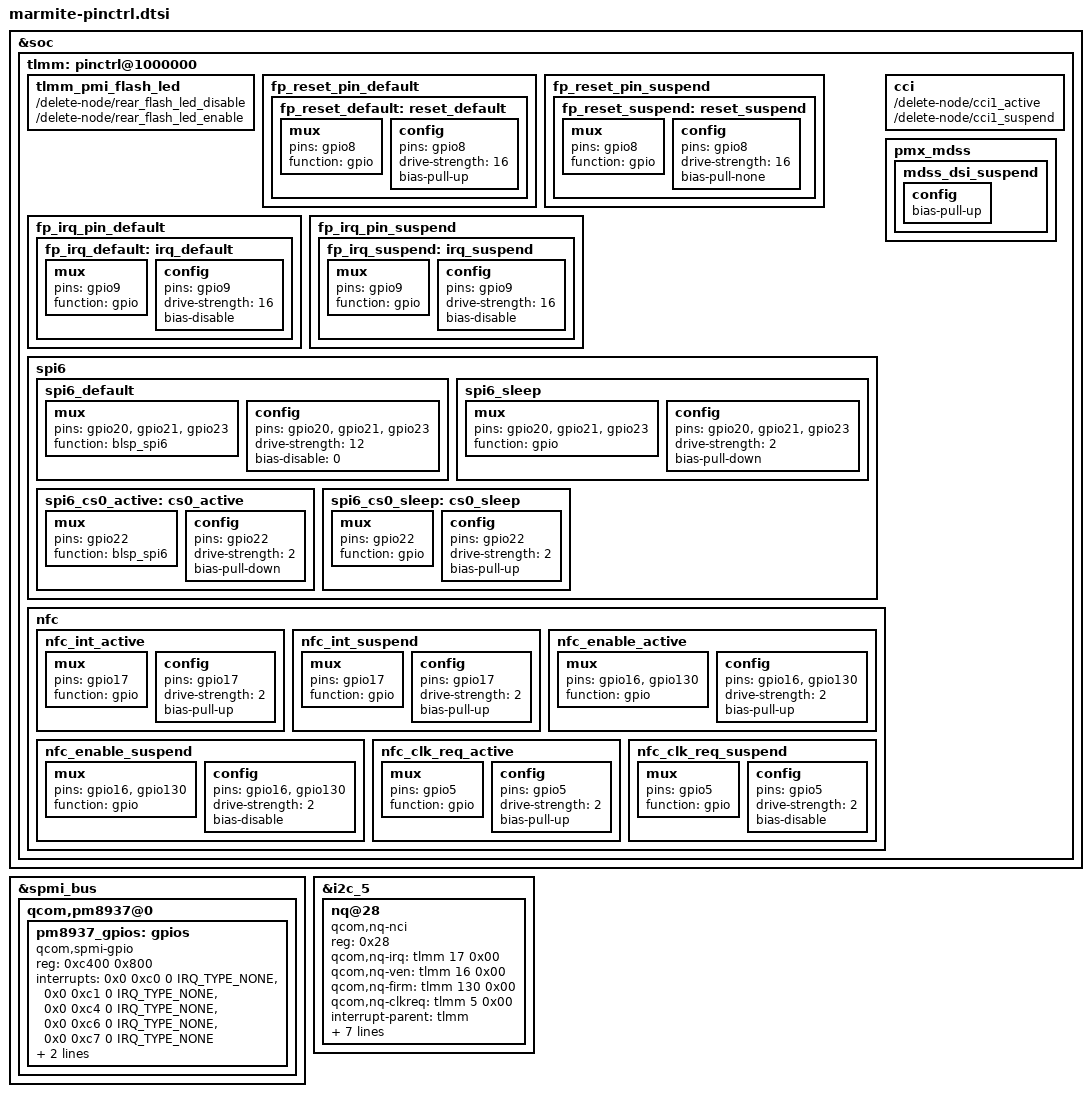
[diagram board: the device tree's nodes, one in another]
/* Copyright (c) 2020, The Linux Foundation. All rights reserved.
*  Copyright (c) 2020, Jebaitedneko.
*
* This program is free software; you can redistribute it and/or modify
* it under the terms of the GNU General Public License version 2 and
* only version 2 as published by the Free Software Foundation.
*
* This program is distributed in the hope that it will be useful,
* but WITHOUT ANY WARRANTY; without even the implied warranty of
* MERCHANTABILITY or FITNESS FOR A PARTICULAR PURPOSE.  See the
* GNU General Public License for more details.
*/

&soc {

	tlmm: pinctrl@1000000 {
		 tlmm_pmi_flash_led {
			  rear_flash_led_disable: /delete-node/rear_flash_led_disable;
			  rear_flash_led_enable: /delete-node/rear_flash_led_enable;
		 };
		 fp_reset_pin_default {
			  fp_reset_default: reset_default {
				   mux {
					    pins = "gpio8";
					    function = "gpio";
				   };

				   config {
					    pins = "gpio8";
					    drive-strength = <16>;
					    bias-pull-up;
				   };
			  };
		 };
		 fp_reset_pin_suspend {
			  fp_reset_suspend: reset_suspend {
				   mux {
					    pins = "gpio8";
					    function = "gpio";
				   };

				   config {
					    pins = "gpio8";
					    drive-strength = <16>;
					    bias-pull-none;
				   };
			  };
		 };

		 fp_irq_pin_default {
			  fp_irq_default: irq_default {
				   mux {
					    pins = "gpio9";
					    function = "gpio";
				   };

				   config {
					    pins = "gpio9";
					    drive-strength = <16>;
					    bias-disable;
				   };
			  };
		 };
		 fp_irq_pin_suspend {
			  fp_irq_suspend: irq_suspend {
				   mux {
					    pins = "gpio9";
					    function = "gpio";
				   };

				   config {
					    pins = "gpio9";
					    drive-strength = <16>;
					    bias-disable;
				   };
			  };
		 };

		 spi6 {
			  spi6_default: spi6_default {
				   mux {
					    pins = "gpio20", "gpio21", "gpio23";
					    function = "blsp_spi6";
				   };

				   config {
					    pins = "gpio20", "gpio21", "gpio23";
					    drive-strength = <12>;
					    bias-disable = <0>;
				   };
			  };

			  spi6_sleep: spi6_sleep {
				   mux {
					    pins = "gpio20", "gpio21", "gpio23";
					    function = "gpio";
				   };

				   config {
					    pins = "gpio20", "gpio21", "gpio23";
					    drive-strength = <2>;
					    bias-pull-down;
				   };
			  };

			  spi6_cs0_active: cs0_active {
				   mux {
					    pins = "gpio22";
					    function = "blsp_spi6";
				   };

				   config {
					    pins = "gpio22";
					    drive-strength = <2>;
					    bias-pull-down;
				   };
			  };

			  spi6_cs0_sleep: cs0_sleep {
				   mux {
					    pins = "gpio22";
					    function = "gpio";
				   };

				   config {
					    pins = "gpio22";
					    drive-strength = <2>;
					    bias-pull-up;
				   };
			  };
		 };

		cci {
			cci1_active: /delete-node/cci1_active;
			cci1_suspend: /delete-node/cci1_suspend;
		};

		pmx_mdss: pmx_mdss {
			mdss_dsi_suspend: mdss_dsi_suspend {
				config {	
					/delete-property/bias-pull-down;
					bias-pull-up;
				};
			};
		};

		nfc {
			nfc_int_active: nfc_int_active {
				/* active state */
				mux {
					/* GPIO 47 NFC Read Interrupt */
					pins = "gpio17";
					function = "gpio";
				};

				config {
					pins = "gpio17";
					drive-strength = <2>; /* 2 MA */
					bias-pull-up;
				};
			};

			nfc_int_suspend: nfc_int_suspend {
				/* sleep state */
				mux {
					/* GPIO 47 NFC Read Interrupt */
					pins = "gpio17";
					function = "gpio";
				};

				config {
					pins = "gpio17";
					drive-strength = <2>; /* 2 MA */
					bias-pull-up;
				};
			};

			nfc_enable_active: nfc_enable_active {
				/* active state */
    				mux {
      					/* 16: NFC ENABLE; 130:NFC FIRM */
      					pins = "gpio16", "gpio130";
      					function = "gpio";
    				};

    				config {
      					pins = "gpio16", "gpio130";
      					drive-strength = <2>; /* 2 MA */
      					bias-pull-up;
    				};
  			};

			nfc_enable_suspend: nfc_enable_suspend {
    				/* sleep state */
    				mux {
      					pins = "gpio16", "gpio130";
      					function = "gpio";
    				};

    				config {
      					pins = "gpio16", "gpio130";
      					drive-strength = <2>; /* 2 MA */
      					bias-disable;
    				};
  			};

  			nfc_clk_req_active: nfc_clk_req_active {
    				/* active state */
    				mux {
      					/* 31: NFC CLOCK REQUEST */
      					pins = "gpio5";
      					function = "gpio";
    				};

    				config {
      					pins = "gpio5";
      					drive-strength = <2>; /* 2 MA */
      					bias-pull-up;
   				};
  			};

 			nfc_clk_req_suspend: nfc_clk_req_suspend {
				/* sleep state */
    				mux {
      					/* 113: NFC CLOCK REQUEST */
      					pins = "gpio5";
      					function = "gpio";
    				};

    				config {
      					pins = "gpio5";
      					drive-strength = <2>; /* 2 MA */
      					bias-disable;
    				};
  			};
		};
	};
};

&spmi_bus {
	qcom,pm8937@0 {
		pm8937_gpios: gpios {
			compatible = "qcom,spmi-gpio";
			/* shifted from <0xc000 0x800>, refer dmesg to get your shifts */
			reg = <0xc400 0x800>;
			interrupts = <0x0 0xc0 0 IRQ_TYPE_NONE>,
				     <0x0 0xc1 0 IRQ_TYPE_NONE>,
				     <0x0 0xc4 0 IRQ_TYPE_NONE>,
				     <0x0 0xc6 0 IRQ_TYPE_NONE>,
				     <0x0 0xc7 0 IRQ_TYPE_NONE>;
			interrupt-names = "pm8937_gpio1", "pm8937_gpio2",
					  "pm8937_gpio5", "pmi8937_gpio7",
					  "pm8937_gpio8";
			gpio-controller;
			#gpio-cells = <2>;
			qcom,gpios-disallowed = <3 4 6>;
		};
	};
};

&i2c_5 { /* BLSP2 QUP1 (NFC) */
	status = "ok";
  	nq@28 {
		compatible = "qcom,nq-nci";
    		reg = <0x28>;
    		qcom,nq-irq = <&tlmm 17 0x00>;
    		qcom,nq-ven = <&tlmm 16 0x00>;
    		qcom,nq-firm = <&tlmm 130 0x00>;
    		qcom,nq-clkreq = <&tlmm 5 0x00>;
    		interrupt-parent = <&tlmm>;
    		qcom,clk-src = "BBCLK2";
    		interrupts = <17 0>;
    		interrupt-names = "nfc_irq";
        	pinctrl-names = "nfc_active", "nfc_suspend";
        	pinctrl-0 = <&nfc_int_active &nfc_enable_active
                &nfc_clk_req_active>;
        	pinctrl-1 = <&nfc_int_suspend &nfc_enable_suspend
                &nfc_clk_req_suspend>;
    		clocks = <&clock_gcc clk_bb_clk2_pin>;
    		clock-names = "ref_clk";
  	};
};
